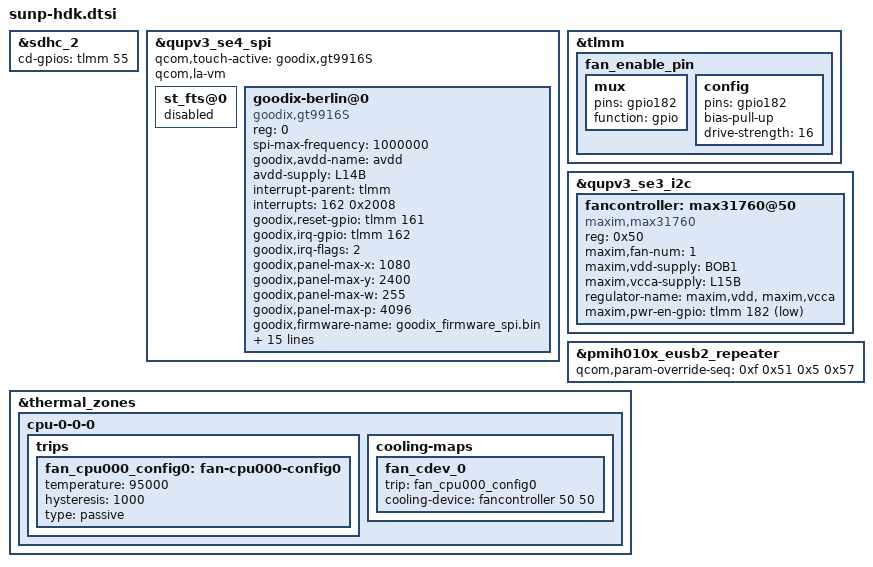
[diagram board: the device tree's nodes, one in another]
// SPDX-License-Identifier: BSD-3-Clause
/*
 * Copyright (c) 2024 Qualcomm Innovation Center, Inc. All rights reserved.
 */

#include "sun-qrd-sku1-v8.dtsi"

&sdhc_2 {
	cd-gpios = <&tlmm 55 GPIO_ACTIVE_HIGH>;
};

&qupv3_se4_spi {
	#address-cells = <1>;
	#size-cells = <0>;
	status = "ok";
	qcom,touch-active = "goodix,gt9916S";
	qcom,la-vm;

	st_fts@0 {
		status = "disabled";
	};

	goodix-berlin@0 {
		compatible = "goodix,gt9916S";
		reg = <0>;
		spi-max-frequency = <1000000>;

		goodix,avdd-name = "avdd";
		avdd-supply = <&L14B>;

		interrupt-parent = <&tlmm>;
		interrupts = <162 0x2008>;
		goodix,reset-gpio = <&tlmm 161 0x00>;
		goodix,irq-gpio = <&tlmm 162 0x2008>;
		goodix,irq-flags = <2>;
		goodix,panel-max-x = <1080>;
		goodix,panel-max-y = <2400>;
		goodix,panel-max-w = <255>;
		goodix,panel-max-p = <4096>;
		goodix,firmware-name = "goodix_firmware_spi.bin";
		goodix,config-name = "goodix_cfg_group_spi.bin";

		pinctrl-names = "pmx_ts_active", "pmx_ts_suspend", "pmx_ts_release";
		pinctrl-0 = <&ts_active>;
		pinctrl-1 = <&ts_int_suspend &ts_reset_suspend>;
		pinctrl-2 = <&ts_release>;

		goodix,touch-type = "primary";
		goodix,qts_en;
		qts,trusted-touch-mode = "vm_mode";
		qts,touch-environment = "pvm";
		qts,trusted-touch-type = "primary";
		qts,trusted-touch-spi-irq = <652>;
		qts,trusted-touch-io-bases = <0xa90000>;
		qts,trusted-touch-io-sizes = <0x1000>;
		qts,trusted-touch-vm-gpio-list = <&tlmm 48 0 &tlmm 49 0 &tlmm 50 0
						&tlmm 51 0 &tlmm 161 0 &tlmm 162 0x2008>;
	};
};

&tlmm {
	fan_enable_pin {
		mux {
			pins = "gpio182";
			function = "gpio";
		};

		config {
			pins = "gpio182";
			bias-pull-up;
			drive-strength = <16>;
		};
	};
};

&qupv3_se3_i2c {
	status = "ok";
	#address-cells = <1>;
	#size-cells = <0>;

	fancontroller: max31760@50 {
		compatible = "maxim,max31760";
		reg = <0x50>;
		#cooling-cells = <2>;
		maxim,fan-num = <1>;
		maxim,vdd-supply = <&BOB1>;
		maxim,vcca-supply = <&L15B>;
		regulator-name = "maxim,vdd", "maxim,vcca";
		maxim,pwr-en-gpio = <&tlmm 182 GPIO_ACTIVE_LOW>;
		status = "ok";
	};
};

&pmih010x_eusb2_repeater {
	qcom,param-override-seq =
		/* <value reg_offset> */
		/* Adjust HS trasmit amplitude */
		<0xf 0x51
		/* Tx pre-emphasis tuning */
		0x5 0x57>;
};

&thermal_zones {
	cpu-0-0-0 {
		trips {
			fan_cpu000_config0: fan-cpu000-config0 {
				temperature = <95000>;
				hysteresis = <1000>;
				type = "passive";
			};
		};

		cooling-maps {
			fan_cdev_0 {
				trip = <&fan_cpu000_config0>;
				cooling-device = <&fancontroller 50 50>;
			};
		};
	};
};
